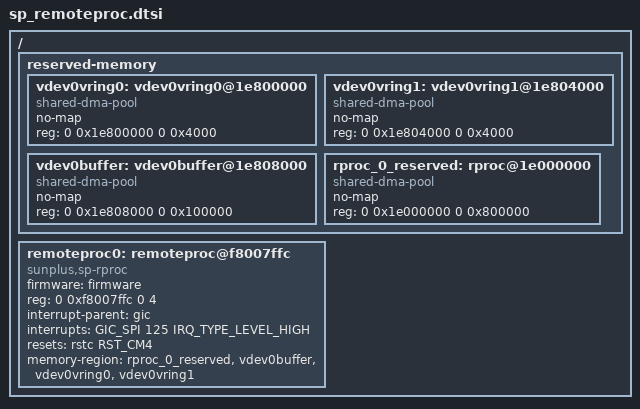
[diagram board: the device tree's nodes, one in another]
/ {
	reserved-memory {
		vdev0vring0: vdev0vring0@1e800000 {
			no-map;
			compatible = "shared-dma-pool";
			reg = <0 0x1e800000 0 0x4000>;
		};
		vdev0vring1: vdev0vring1@1e804000 {
			no-map;
			compatible = "shared-dma-pool";
			reg = <0 0x1e804000 0 0x4000>;
		};
		vdev0buffer: vdev0buffer@1e808000 {
			no-map;
			compatible = "shared-dma-pool";
			reg = <0 0x1e808000 0 0x100000>;
		};
		rproc_0_reserved: rproc@1e000000 {
			no-map;
			compatible = "shared-dma-pool";
			reg = <0 0x1e000000 0 0x800000>;
		};
	};

	remoteproc0: remoteproc@f8007ffc {
		compatible = "sunplus,sp-rproc";
		firmware = "firmware";
		reg = <0 0xf8007ffc 0 4>; /* mbox G255.31, cpu0 to cpu2 direct reg07 */
		interrupt-parent = <&gic>;
		interrupts = <GIC_SPI 125 IRQ_TYPE_LEVEL_HIGH>; /* CPU2_TO_0_DIRECT_INT7 */
		resets = <&rstc RST_CM4>;
		memory-region = <&rproc_0_reserved>, <&vdev0buffer>, <&vdev0vring0>, <&vdev0vring1>;
	};
};
